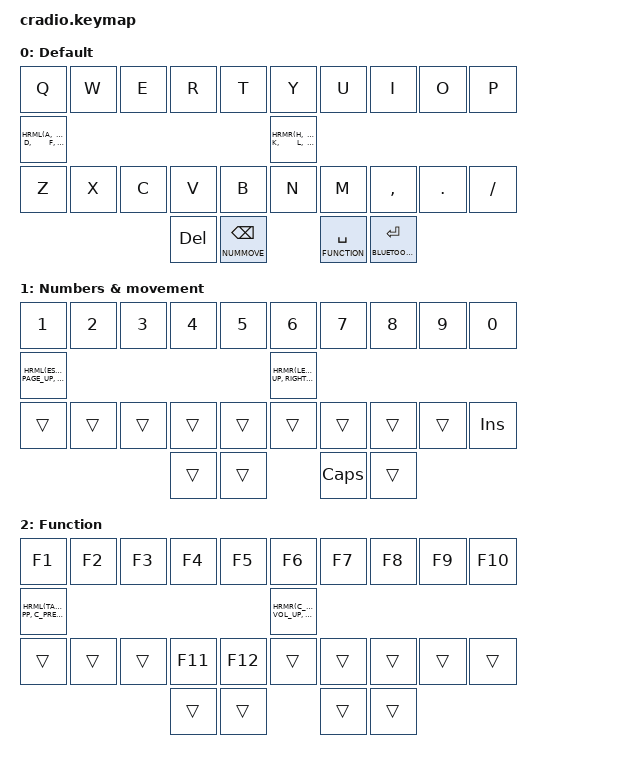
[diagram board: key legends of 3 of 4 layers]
// Copyright (c) 2022 The ZMK Contributors
// SPDX-License-Identifier: MIT

#include <behaviors.dtsi>
#include <dt-bindings/zmk/keys.h>
#include <dt-bindings/zmk/bt.h>

// Home row mods macro
#define HRML(k1,k2,k3,k4,k5) &hml LGUI  k1 &hml LALT  k2 &hml LSHFT k3 &hml LCTRL k4 &hml RALT  k5
#define HRMR(k1,k2,k3,k4,k5) &hmr RALT  k1 &hmr RCTRL k2 &hmr RSHFT k3 &hmr LALT  k4 &hmr RGUI  k5

// Layer defines https://zmk.dev/docs/keymaps/behaviors/layers#defines-to-refer-to-layers
#define DEFAULT 0
#define NUMMOVE 1
#define FUNCTION 2
#define BLUETOOTH 3

/ {
    behaviors {
        ht: hold_tap {
            compatible = "zmk,behavior-hold-tap";
            #binding-cells = <2>;
            flavor = "hold-preferred";
            tapping-term-ms = <180>;
            quick-tap-ms = <150>;
            require-prior-idle-ms = <100>;
            bindings = <&kp>, <&kp>;
        };
        lt: layer_tap {
            compatible = "zmk,behavior-hold-tap";
            #binding-cells = <2>;
            flavor = "hold-preferred";
            tapping-term-ms = <180>;
            quick-tap-ms = <150>;
            bindings = <&mo>, <&kp>;
            display-name = "Layer-Tap";
        };
	hml: home_row_mod_left {
            compatible = "zmk,behavior-hold-tap";
            #binding-cells = <2>;
            flavor = "balanced";
            require-prior-idle-ms = <100>;
            tapping-term-ms = <180>;
            quick-tap-ms = <150>;
            bindings = <&kp>, <&kp>;
            hold-trigger-key-positions = < 5 6 7 8 9 15 16 17 18 19 25 26 27 28 29 32 33 >; // List of keys on the right side of the keyboard
            hold-trigger-on-release;
        };
        hmr: home_row_mod_right {
            compatible = "zmk,behavior-hold-tap";
            #binding-cells = <2>;
            flavor = "balanced";
            require-prior-idle-ms = <100>;
            tapping-term-ms = <180>;
            quick-tap-ms = <150>;
            bindings = <&kp>, <&kp>;
            hold-trigger-key-positions = < 0 1 2 3 4 10 11 12 13 14 20 21 22 23 24 30 31 >; // List of keys on the left side of the keyboard
            hold-trigger-on-release;
        };
    };


    keymap {
        compatible = "zmk,keymap";
	default_layer {
	    display-name = "Default";
	    bindings = <
        //╭──────────┬──────────┬──────────┬──────────┬──────────╮   ╭──────────┬──────────┬──────────┬──────────┬──────────╮
        //│  Q       │  W       │  E       │  R       │  T       │   │  Y       │  U       │  I       │  O       │  P       │
            &kp Q      &kp W      &kp E      &kp R      &kp T          &kp Y      &kp U      &kp I      &kp O      &kp P
        //├──────────┼──────────┼──────────┼──────────┼──────────┤   ├──────────┼──────────┼──────────┼──────────┼──────────┤
        //│  A       │  S       │  D       │  F       │  G       │   │  H       │  J       │  K       │  L       │  :       │
            HRML(A,        S,         D,         F,       G)          HRMR(H,        J,        K,         L,        SEMI)
        //├──────────┼──────────┼──────────┼──────────┼──────────┤   ├──────────┼──────────┼──────────┼──────────┼──────────┤
        //│  Z       │  X       │  C       │  V       │  B       │   │  N       │  M       │ , <      │ . >      │ / ?      │
            &kp Z      &kp X      &kp C      &kp V      &kp B          &kp N      &kp M      &kp COMMA  &kp DOT    &kp FSLH
        //╰──────────┴──────────┴──────────┼──────────┼──────────┤   ├──────────┼──────────┼──────────┴──────────┴──────────╯
                                           &kp DEL   &lt NUMMOVE BSPC &lt FUNCTION SPACE &lt BLUETOOTH RET
        //                                 ╰──────────┴──────────╯   ╰──────────┴──────────╯
            >;
        };
        nummove_layer {
	    display-name = "Numbers & movement";
            bindings = <
        //╭──────────┬──────────┬──────────┬──────────┬──────────╮   ╭──────────┬──────────┬──────────┬──────────┬──────────╮
        //│    1     │    2     │   3      │    4     │   5      │   │    6     │    7     │   8      │    9     │    0     │
             &kp N1     &kp N2     &kp N3     &kp N4     &kp N5         &kp N6     &kp N7     &kp N8     &kp N9    &kp N0
        //├──────────┼──────────┼──────────┼──────────┼──────────┤   ├──────────┼──────────┼──────────┼──────────┼──────────┤
        //│ ESCAPE   │PAGE DOWN │PAGE UP   │ HOME     │ END      │   │  LEFT    │ DOWN     │  UP      │  RIGHT   │PRINT SCRN│
           HRML(ESC, PAGE_DOWN, PAGE_UP, HOME, END)                  HRMR(LEFT, DOWN, UP, RIGHT, PSCRN)
        //├──────────┼──────────┼──────────┼──────────┼──────────┤   ├──────────┼──────────┼──────────┼──────────┼──────────┤
        //│          │          │          │          │          │   │          │          │          │          │  INSERT  │
           &trans       &trans     &trans     &trans     &trans         &trans     &trans     &trans     &trans    &kp INSERT
        //╰──────────┴──────────┴──────────┼──────────┼──────────┤   ├──────────┼──────────┼──────────┴──────────┴──────────╯
                                             &trans     &trans         &kp CAPS     &trans
        //                                 ╰──────────┴──────────╯   ╰──────────┴──────────╯
            >;
        };
        function_layer {
	    display-name = "Function";
            bindings = <
        //╭──────────┬──────────┬──────────┬──────────┬──────────╮   ╭──────────┬──────────┬──────────┬──────────┬──────────╮
        //│    F1    │    F2    │   F3     │    F4    │   F5     │   │    F6    │    F7    │   F8     │    F9    │    F10   │
             &kp F1     &kp F2     &kp F3     &kp F4     &kp F5         &kp F6     &kp F7     &kp F8     &kp F9    &kp F10
        //├──────────┼──────────┼──────────┼──────────┼──────────┤   ├──────────┼──────────┼──────────┼──────────┼──────────┤
        //│ TAB      │  STOP    │PLAY/PAUSE│PREVIOUS  │NEXT      │   │  MUTE    │ VOL DOWN │  VOL UP  │BRIGHT DWN│BRIGHT UP │
            HRML(TAB, C_STOP, C_PP, C_PREV, C_NEXT)                       HRMR(C_MUTE, C_VOL_DN, C_VOL_UP, C_BRI_DN, C_BRI_UP)
        //├──────────┼──────────┼──────────┼──────────┼──────────┤   ├──────────┼──────────┼──────────┼──────────┼──────────┤
        //│          │          │          │ F11      │ F12      │   │          │          │          │          │          │
            &trans     &trans     &trans    &kp F11    &kp F12           &trans     &trans     &trans    &trans     &trans
        //╰──────────┴──────────┴──────────┼──────────┼──────────┤   ├──────────┼──────────┼──────────┴──────────┴──────────╯
                                             &trans     &trans         &trans     &trans
        //                                 ╰──────────┴──────────╯   ╰──────────┴──────────╯
            >;
        };
        bluetooth_layer {
	    display-name = "Bluetooth";
            bindings = <
        //╭──────────┬──────────┬──────────┬──────────┬──────────╮   ╭──────────┬──────────┬──────────┬──────────┬──────────╮
        //│    BT 1  │    BT 2  │  BT 3    │   BT 4   │   BT 5   │   │  BT CLR  │          │          │          │BT CLR ALL│
     &bt BT_SEL 1 &bt BT_SEL 2 &bt BT_SEL 3 &bt BT_SEL 4 &bt BT_SEL 5 &bt BT_CLR  &trans     &trans     &trans    &bt BT_CLR_ALL
        //├──────────┼──────────┼──────────┼──────────┼──────────┤   ├──────────┼──────────┼──────────┼──────────┼──────────┤
        //│ DISC BT1 │ DISC BT2 │ DISC BT3 │ DISC BT4 │ DISC BT5 │   │          │          │          │          │          │
            &bt BT_DISC 1     &bt BT_DISC 2     &bt BT_DISC 3      &bt BT_DISC 4     &bt BT_DISC 5         &trans     &trans     &trans    &trans     &trans
        //├──────────┼──────────┼──────────┼──────────┼──────────┤   ├──────────┼──────────┼──────────┼──────────┼──────────┤
        //│          │          │          │          │          │   │          │          │          │          │          │
           &trans      &trans       &trans     &trans    &trans        &trans       &trans     &trans     &trans    &trans
        //╰──────────┴──────────┴──────────┼──────────┼──────────┤   ├──────────┼──────────┼──────────┴──────────┴──────────╯
                                             &trans     &trans         &trans     &trans
        //                                 ╰──────────┴──────────╯   ╰──────────┴──────────╯
            >;
        };
    };
};
